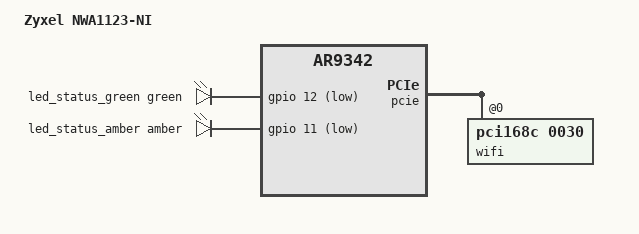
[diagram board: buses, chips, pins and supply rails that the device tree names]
// SPDX-License-Identifier: GPL-2.0-or-later OR MIT

#include <dt-bindings/leds/common.h>

#include "ar9342_zyxel_nwa11xx.dtsi"

/ {
	compatible = "zyxel,nwa1123-ni", "qca,ar9342";
	model = "Zyxel NWA1123-NI";

	aliases {
		label-mac-device = &eth0;
		led-boot = &led_status_green;
		led-failsafe = &led_status_amber;
		led-running = &led_status_green;
		led-upgrade = &led_status_amber;
	};

	leds {
		compatible = "gpio-leds";

		led_status_green: status_green {
			function = LED_FUNCTION_STATUS;
			color = <LED_COLOR_ID_GREEN>;
			gpios = <&gpio 12 GPIO_ACTIVE_LOW>;
			default-state = "on";
		};

		led_status_amber: status_amber {
			function = LED_FUNCTION_STATUS;
			color = <LED_COLOR_ID_AMBER>;
			gpios = <&gpio 11 GPIO_ACTIVE_LOW>;
		};
	};
};

&pcie {
	status = "okay";

	wifi@0,0 {
		compatible = "pci168c,0030";
		reg = <0x0000 0 0 0 0>;
		nvmem-cells = <&macaddr_mib0_66 0>;
		nvmem-cell-names = "mac-address";
	};
};
